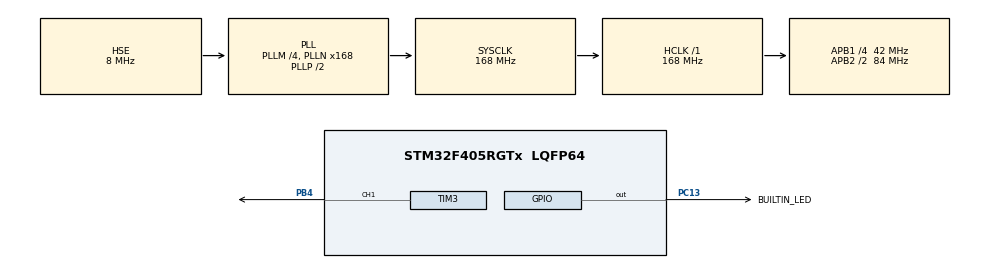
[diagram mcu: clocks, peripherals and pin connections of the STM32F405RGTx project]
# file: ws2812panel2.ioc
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Dma.Request0=TIM3_CH1/TRIG
Dma.TIM3_CH1/TRIG.0.Direction=DMA_MEMORY_TO_PERIPH
Dma.TIM3_CH1/TRIG.0.FIFOMode=DMA_FIFOMODE_DISABLE
Dma.TIM3_CH1/TRIG.0.Instance=DMA1_Stream4
Dma.TIM3_CH1/TRIG.0.MemDataAlignment=DMA_MDATAALIGN_HALFWORD
Dma.TIM3_CH1/TRIG.0.MemInc=DMA_MINC_ENABLE
Dma.TIM3_CH1/TRIG.0.Mode=DMA_CIRCULAR
Dma.TIM3_CH1/TRIG.0.PeriphDataAlignment=DMA_PDATAALIGN_HALFWORD
Dma.TIM3_CH1/TRIG.0.PeriphInc=DMA_PINC_DISABLE
Dma.TIM3_CH1/TRIG.0.Priority=DMA_PRIORITY_LOW
Mcu.Family=STM32F4
Mcu.Name=STM32F405RGTx
Mcu.Package=LQFP64
Mcu.UserConstants=T3_PRE,0;T3_CNT,104
NVIC.DMA1_Stream4_IRQn=true\:0\:0\:false\:false\:true\:false\:true
NVIC.PriorityGroup=NVIC_PRIORITYGROUP_4
PA13.Mode=Serial_Wire
PA13.Signal=SYS_JTMS-SWDIO
PA14.Mode=Serial_Wire
PA14.Signal=SYS_JTCK-SWCLK
PB4.GPIO_Speed=GPIO_SPEED_FREQ_HIGH
PB4.Signal=S_TIM3_CH1
PC13-ANTI_TAMP.GPIO_Label=BUILTIN_LED
PC13-ANTI_TAMP.GPIO_ModeDefaultOutputPP=GPIO_MODE_OUTPUT_OD
PC13-ANTI_TAMP.PinState=GPIO_PIN_SET
PC13-ANTI_TAMP.Signal=GPIO_Output
PH0-OSC_IN.Mode=HSE-External-Oscillator
PH0-OSC_IN.Signal=RCC_OSC_IN
PH1-OSC_OUT.Mode=HSE-External-Oscillator
PH1-OSC_OUT.Signal=RCC_OSC_OUT
ProjectManager.HeapSize=0x200
ProjectManager.StackSize=0x400
ProjectManager.TargetToolchain=STM32CubeIDE
RCC.48MHZClocksFreq_Value=84000000
RCC.AHBFreq_Value=168000000
RCC.APB1CLKDivider=RCC_HCLK_DIV4
RCC.APB1Freq_Value=42000000
RCC.APB1TimFreq_Value=84000000
RCC.APB2CLKDivider=RCC_HCLK_DIV2
RCC.APB2Freq_Value=84000000
RCC.APB2TimFreq_Value=168000000
RCC.CortexFreq_Value=168000000
RCC.HCLKFreq_Value=168000000
RCC.HSE_VALUE=8000000
RCC.HSI_VALUE=16000000
RCC.LSE_VALUE=32768
RCC.PLLM=4
RCC.PLLN=168
RCC.PLLSourceVirtual=RCC_PLLSOURCE_HSE
RCC.SYSCLKFreq_VALUE=168000000
RCC.SYSCLKSource=RCC_SYSCLKSOURCE_PLLCLK
RCC.VCOOutputFreq_Value=336000000
SH.S_TIM3_CH1.0=TIM3_CH1,PWM Generation1 CH1
TIM3.AutoReloadPreload=TIM_AUTORELOAD_PRELOAD_ENABLE
TIM3.Channel-PWM\ Generation1\ CH1=TIM_CHANNEL_1
TIM3.OC1Preload_PWM=ENABLE
TIM3.OCFastMode_PWM-PWM\ Generation1\ CH1=TIM_OCFAST_ENABLE
TIM3.Period=T3_CNT
TIM3.Prescaler=T3_PRE
TIM3.TIM_MasterOutputTrigger=TIM_TRGO_UPDATE
VP_TIM3_VS_ClockSourceINT.Mode=Internal
board=custom

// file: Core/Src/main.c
/* USER CODE BEGIN Header */
/**
  ******************************************************************************
  * @file           : main.c
  * @brief          : Main program body
  ******************************************************************************
  * @attention
  *
  * <h2><center>&copy; Copyright (c) 2021 lbthomsen@gmail.com.
  * All rights reserved.</center></h2>
  *
  * This software component is licensed by lbthomsen under MIT license,
  * the "License"; You may not use this file except in compliance with the
  * License. You may obtain a copy of the License at:
  *                        opensource.org/licenses/MIT
  *
  ******************************************************************************
  */
/* USER CODE END Header */
#include "main.h"

/* USER CODE BEGIN Includes */
#include "ws2812b.h"
/* USER CODE END Includes */

/* USER CODE BEGIN PD */
#define T3_CNT 104
#define T3_PRE 0
#define T4_PRE 8399
#define T4_CNT 99

#define LED_COLS 8
#define LED_ROWS 8
/* USER CODE END PD */

TIM_HandleTypeDef htim3;
DMA_HandleTypeDef hdma_tim3_ch1_trig;

void SystemClock_Config(void);
static void MX_GPIO_Init(void);
static void MX_DMA_Init(void);
static void MX_TIM3_Init(void);

int main(void)
{

  /* MCU Configuration--------------------------------------------------------*/

  /* Reset of all peripherals, Initializes the Flash interface and the Systick. */
  HAL_Init();

  /* Configure the system clock */
  SystemClock_Config();

  /* Initialize all configured peripherals */
  MX_GPIO_Init();
  MX_DMA_Init();
  MX_TIM3_Init();
  /* USER CODE BEGIN 2 */

  ws2812b_init(&htim3, TIM_CHANNEL_1, LED_ROWS, LED_COLS);

  //setLedValues(0, 0, 50, 0, 0);
  setLedValues(1, 0, 0, 50, 0);
  setLedValues(2, 0, 0, 0, 50);
  //setLedValues(3, 0, 50, 0, 50);
  //setLedValues(4, 0, 50, 50, 0);
  //setLedValues(5, 0, 0, 50, 50);
  //setLedValues(6, 0, 10, 10, 10);
  //setLedValues(7, 0, 20, 20, 20);

  /* USER CODE END 2 */

  /* Infinite loop */
  /* USER CODE BEGIN WHILE */

  uint32_t then = 0, now = 0;

  while (1)
  {

	now = HAL_GetTick();
	if (now % 100 == 0 && now != then) {
		HAL_GPIO_TogglePin(BUILTIN_LED_GPIO_Port, BUILTIN_LED_Pin);
		then = now;
	}

    /* USER CODE END WHILE */

  }
}

void SystemClock_Config(void)
{
  RCC_OscInitTypeDef RCC_OscInitStruct = {0};
  RCC_ClkInitTypeDef RCC_ClkInitStruct = {0};

  /** Configure the main internal regulator output voltage
  */
  __HAL_RCC_PWR_CLK_ENABLE();
  __HAL_PWR_VOLTAGESCALING_CONFIG(PWR_REGULATOR_VOLTAGE_SCALE1);
  /** Initializes the RCC Oscillators according to the specified parameters
  * in the RCC_OscInitTypeDef structure.
  */
  RCC_OscInitStruct.OscillatorType = RCC_OSCILLATORTYPE_HSE;
  RCC_OscInitStruct.HSEState = RCC_HSE_ON;
  RCC_OscInitStruct.PLL.PLLState = RCC_PLL_ON;
  RCC_OscInitStruct.PLL.PLLSource = RCC_PLLSOURCE_HSE;
  RCC_OscInitStruct.PLL.PLLM = 4;
  RCC_OscInitStruct.PLL.PLLN = 168;
  RCC_OscInitStruct.PLL.PLLP = RCC_PLLP_DIV2;
  RCC_OscInitStruct.PLL.PLLQ = 4;
  if (HAL_RCC_OscConfig(&RCC_OscInitStruct) != HAL_OK)
  {
    Error_Handler();
  }
  /** Initializes the CPU, AHB and APB buses clocks
  */
  RCC_ClkInitStruct.ClockType = RCC_CLOCKTYPE_HCLK|RCC_CLOCKTYPE_SYSCLK
                              |RCC_CLOCKTYPE_PCLK1|RCC_CLOCKTYPE_PCLK2;
  RCC_ClkInitStruct.SYSCLKSource = RCC_SYSCLKSOURCE_PLLCLK;
  RCC_ClkInitStruct.AHBCLKDivider = RCC_SYSCLK_DIV1;
  RCC_ClkInitStruct.APB1CLKDivider = RCC_HCLK_DIV4;
  RCC_ClkInitStruct.APB2CLKDivider = RCC_HCLK_DIV2;

  if (HAL_RCC_ClockConfig(&RCC_ClkInitStruct, FLASH_LATENCY_5) != HAL_OK)
  {
    Error_Handler();
  }
}

static void MX_TIM3_Init(void)
{

  TIM_ClockConfigTypeDef sClockSourceConfig = {0};
  TIM_MasterConfigTypeDef sMasterConfig = {0};
  TIM_OC_InitTypeDef sConfigOC = {0};

  htim3.Instance = TIM3;
  htim3.Init.Prescaler = T3_PRE;
  htim3.Init.CounterMode = TIM_COUNTERMODE_UP;
  htim3.Init.Period = T3_CNT;
  htim3.Init.ClockDivision = TIM_CLOCKDIVISION_DIV1;
  htim3.Init.AutoReloadPreload = TIM_AUTORELOAD_PRELOAD_ENABLE;
  if (HAL_TIM_Base_Init(&htim3) != HAL_OK)
  {
    Error_Handler();
  }
  sClockSourceConfig.ClockSource = TIM_CLOCKSOURCE_INTERNAL;
  if (HAL_TIM_ConfigClockSource(&htim3, &sClockSourceConfig) != HAL_OK)
  {
    Error_Handler();
  }
  if (HAL_TIM_PWM_Init(&htim3) != HAL_OK)
  {
    Error_Handler();
  }
  sMasterConfig.MasterOutputTrigger = TIM_TRGO_UPDATE;
  sMasterConfig.MasterSlaveMode = TIM_MASTERSLAVEMODE_DISABLE;
  if (HAL_TIMEx_MasterConfigSynchronization(&htim3, &sMasterConfig) != HAL_OK)
  {
    Error_Handler();
  }
  sConfigOC.OCMode = TIM_OCMODE_PWM1;
  sConfigOC.Pulse = 0;
  sConfigOC.OCPolarity = TIM_OCPOLARITY_HIGH;
  sConfigOC.OCFastMode = TIM_OCFAST_ENABLE;
  if (HAL_TIM_PWM_ConfigChannel(&htim3, &sConfigOC, TIM_CHANNEL_1) != HAL_OK)
  {
    Error_Handler();
  }
  HAL_TIM_MspPostInit(&htim3);

}

static void MX_DMA_Init(void)
{

  /* DMA controller clock enable */
  __HAL_RCC_DMA1_CLK_ENABLE();

  /* DMA interrupt init */
  /* DMA1_Stream4_IRQn interrupt configuration */
  HAL_NVIC_SetPriority(DMA1_Stream4_IRQn, 0, 0);
  HAL_NVIC_EnableIRQ(DMA1_Stream4_IRQn);

}

static void MX_GPIO_Init(void)
{
  GPIO_InitTypeDef GPIO_InitStruct = {0};

  /* GPIO Ports Clock Enable */
  __HAL_RCC_GPIOC_CLK_ENABLE();
  __HAL_RCC_GPIOH_CLK_ENABLE();
  __HAL_RCC_GPIOA_CLK_ENABLE();
  __HAL_RCC_GPIOB_CLK_ENABLE();

  /*Configure GPIO pin Output Level */
  HAL_GPIO_WritePin(BUILTIN_LED_GPIO_Port, BUILTIN_LED_Pin, GPIO_PIN_SET);

  /*Configure GPIO pin : BUILTIN_LED_Pin */
  GPIO_InitStruct.Pin = BUILTIN_LED_Pin;
  GPIO_InitStruct.Mode = GPIO_MODE_OUTPUT_OD;
  GPIO_InitStruct.Pull = GPIO_NOPULL;
  GPIO_InitStruct.Speed = GPIO_SPEED_FREQ_LOW;
  HAL_GPIO_Init(BUILTIN_LED_GPIO_Port, &GPIO_InitStruct);

}

void Error_Handler(void)
{
  __disable_irq();
  while (1)
  {
  }
}

/************************ (C) COPYRIGHT STMicroelectronics *****END OF FILE****/
